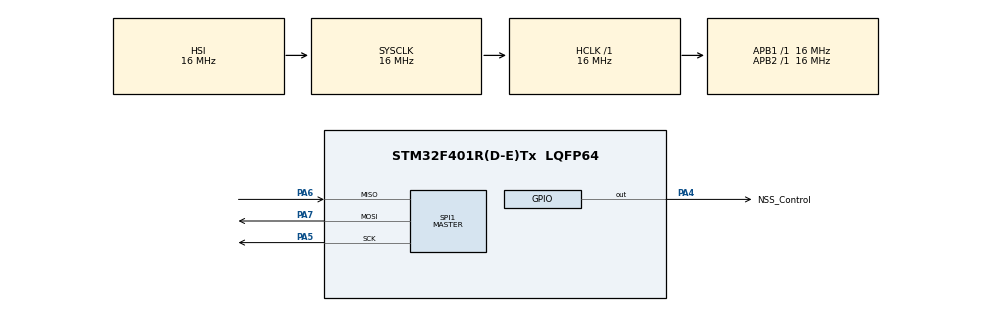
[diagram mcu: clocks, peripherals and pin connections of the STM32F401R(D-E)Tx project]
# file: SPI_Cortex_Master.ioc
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Dma.Request0=SPI1_RX
Dma.Request1=SPI1_TX
Dma.SPI1_RX.0.Direction=DMA_PERIPH_TO_MEMORY
Dma.SPI1_RX.0.FIFOMode=DMA_FIFOMODE_DISABLE
Dma.SPI1_RX.0.Instance=DMA2_Stream0
Dma.SPI1_RX.0.MemDataAlignment=DMA_MDATAALIGN_BYTE
Dma.SPI1_RX.0.MemInc=DMA_MINC_ENABLE
Dma.SPI1_RX.0.Mode=DMA_CIRCULAR
Dma.SPI1_RX.0.PeriphDataAlignment=DMA_PDATAALIGN_BYTE
Dma.SPI1_RX.0.PeriphInc=DMA_PINC_DISABLE
Dma.SPI1_RX.0.Priority=DMA_PRIORITY_LOW
Dma.SPI1_TX.1.Direction=DMA_MEMORY_TO_PERIPH
Dma.SPI1_TX.1.FIFOMode=DMA_FIFOMODE_DISABLE
Dma.SPI1_TX.1.Instance=DMA2_Stream3
Dma.SPI1_TX.1.MemDataAlignment=DMA_MDATAALIGN_BYTE
Dma.SPI1_TX.1.MemInc=DMA_MINC_ENABLE
Dma.SPI1_TX.1.Mode=DMA_CIRCULAR
Dma.SPI1_TX.1.PeriphDataAlignment=DMA_PDATAALIGN_BYTE
Dma.SPI1_TX.1.PeriphInc=DMA_PINC_DISABLE
Dma.SPI1_TX.1.Priority=DMA_PRIORITY_LOW
Mcu.Family=STM32F4
Mcu.Name=STM32F401R(D-E)Tx
Mcu.Package=LQFP64
NVIC.DMA2_Stream0_IRQn=true\:0\:0\:false\:false\:true\:false
NVIC.DMA2_Stream3_IRQn=true\:0\:0\:false\:false\:true\:false
NVIC.PriorityGroup=NVIC_PRIORITYGROUP_4
NVIC.SPI1_IRQn=true\:0\:0\:false\:false\:true\:true
PA4.GPIO_Label=NSS_Control
PA4.GPIO_Speed=GPIO_SPEED_FREQ_HIGH
PA4.Signal=GPIO_Output
PA5.Mode=Full_Duplex_Master
PA5.Signal=SPI1_SCK
PA6.Mode=Full_Duplex_Master
PA6.Signal=SPI1_MISO
PA7.Mode=Full_Duplex_Master
PA7.Signal=SPI1_MOSI
ProjectManager.HeapSize=0x200
ProjectManager.StackSize=0x400
ProjectManager.TargetToolchain=EWARM
RCC.AHBFreq_Value=16000000
RCC.APB1Freq_Value=16000000
RCC.APB2Freq_Value=16000000
RCC.CortexFreq_Value=16000000
RCC.HSE_VALUE=25000000
RCC.HSI_VALUE=16000000
RCC.LSE_VALUE=32768
RCC.SYSCLKFreq_VALUE=16000000
RCC.VCOOutputFreq_Value=192000000
SPI1.BaudRatePrescaler=SPI_BAUDRATEPRESCALER_8
SPI1.Direction=SPI_DIRECTION_2LINES
SPI1.Mode=SPI_MODE_MASTER
SPI1.VirtualType=VM_MASTER
board=SPI_Cortex_Master

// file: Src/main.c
/**
  ******************************************************************************
  * @file           : main.c
  * @brief          : Main program body
  ******************************************************************************
  ** This notice applies to any and all portions of this file
  * that are not between comment pairs USER CODE BEGIN and
  * USER CODE END. Other portions of this file, whether
  * inserted by the user or by software development tools
  * are owned by their respective copyright owners.
  *
  * COPYRIGHT(c) 2020 STMicroelectronics
  *
  * Redistribution and use in source and binary forms, with or without modification,
  * are permitted provided that the following conditions are met:
  *   1. Redistributions of source code must retain the above copyright notice,
  *      this list of conditions and the following disclaimer.
  *   2. Redistributions in binary form must reproduce the above copyright notice,
  *      this list of conditions and the following disclaimer in the documentation
  *      and/or other materials provided with the distribution.
  *   3. Neither the name of STMicroelectronics nor the names of its contributors
  *      may be used to endorse or promote products derived from this software
  *      without specific prior written permission.
  *
  * THIS SOFTWARE IS PROVIDED BY THE COPYRIGHT HOLDERS AND CONTRIBUTORS "AS IS"
  * AND ANY EXPRESS OR IMPLIED WARRANTIES, INCLUDING, BUT NOT LIMITED TO, THE
  * IMPLIED WARRANTIES OF MERCHANTABILITY AND FITNESS FOR A PARTICULAR PURPOSE ARE
  * DISCLAIMED. IN NO EVENT SHALL THE COPYRIGHT HOLDER OR CONTRIBUTORS BE LIABLE
  * FOR ANY DIRECT, INDIRECT, INCIDENTAL, SPECIAL, EXEMPLARY, OR CONSEQUENTIAL
  * DAMAGES (INCLUDING, BUT NOT LIMITED TO, PROCUREMENT OF SUBSTITUTE GOODS OR
  * SERVICES; LOSS OF USE, DATA, OR PROFITS; OR BUSINESS INTERRUPTION) HOWEVER
  * CAUSED AND ON ANY THEORY OF LIABILITY, WHETHER IN CONTRACT, STRICT LIABILITY,
  * OR TORT (INCLUDING NEGLIGENCE OR OTHERWISE) ARISING IN ANY WAY OUT OF THE USE
  * OF THIS SOFTWARE, EVEN IF ADVISED OF THE POSSIBILITY OF SUCH DAMAGE.
  *
  ******************************************************************************
  */
#include "main.h"
#include "stm32f4xx_hal.h"

SPI_HandleTypeDef hspi1;
DMA_HandleTypeDef hdma_spi1_rx;
DMA_HandleTypeDef hdma_spi1_tx;

/* USER CODE BEGIN PV */
/* Private variables ---------------------------------------------------------*/

/* USER CODE END PV */

void SystemClock_Config(void);
static void MX_GPIO_Init(void);
static void MX_DMA_Init(void);
static void MX_SPI1_Init(void);

/* USER CODE BEGIN PFP */
/* Private function prototypes -----------------------------------------------*/

/* USER CODE END PFP */

/* USER CODE BEGIN 0 */
uint8_t dataTx[6] = {9,7,0,7,2,2};
uint8_t dataRx[6];

#define SPI_En          HAL_GPIO_WritePin(GPIOA,GPIO_PIN_4,GPIO_PIN_RESET);
#define SPI_Dis         HAL_GPIO_WritePin(GPIOA,GPIO_PIN_4,GPIO_PIN_SET);
/* USER CODE END 0 */

int main(void)
{

  /* MCU Configuration----------------------------------------------------------*/

  /* Reset of all peripherals, Initializes the Flash interface and the Systick. */
  HAL_Init();

  /* Configure the system clock */
  SystemClock_Config();

  /* Initialize all configured peripherals */
  MX_GPIO_Init();
  MX_DMA_Init();
  MX_SPI1_Init();
  /* USER CODE BEGIN 2 */
  //HAL_SPI_TransmitReceive_IT(&hspi1, dataTx, dataRx, 6);
  //HAL_SPI_TransmitReceive_DMA(&hspi1, dataTx, dataRx, 6);
  /* USER CODE END 2 */

  /* Infinite loop */
  while (1)
  {
    HAL_SPI_Transmit(&hspi1,dataTx, 6,100);
    HAL_Delay(500);
  }

}

void SystemClock_Config(void)
{

  RCC_OscInitTypeDef RCC_OscInitStruct;
  RCC_ClkInitTypeDef RCC_ClkInitStruct;

    /**Configure the main internal regulator output voltage
    */
  __HAL_RCC_PWR_CLK_ENABLE();

  __HAL_PWR_VOLTAGESCALING_CONFIG(PWR_REGULATOR_VOLTAGE_SCALE2);

    /**Initializes the CPU, AHB and APB busses clocks
    */
  RCC_OscInitStruct.OscillatorType = RCC_OSCILLATORTYPE_HSI;
  RCC_OscInitStruct.HSIState = RCC_HSI_ON;
  RCC_OscInitStruct.HSICalibrationValue = 16;
  RCC_OscInitStruct.PLL.PLLState = RCC_PLL_NONE;
  if (HAL_RCC_OscConfig(&RCC_OscInitStruct) != HAL_OK)
  {
    _Error_Handler(__FILE__, __LINE__);
  }

    /**Initializes the CPU, AHB and APB busses clocks
    */
  RCC_ClkInitStruct.ClockType = RCC_CLOCKTYPE_HCLK|RCC_CLOCKTYPE_SYSCLK
                              |RCC_CLOCKTYPE_PCLK1|RCC_CLOCKTYPE_PCLK2;
  RCC_ClkInitStruct.SYSCLKSource = RCC_SYSCLKSOURCE_HSI;
  RCC_ClkInitStruct.AHBCLKDivider = RCC_SYSCLK_DIV1;
  RCC_ClkInitStruct.APB1CLKDivider = RCC_HCLK_DIV1;
  RCC_ClkInitStruct.APB2CLKDivider = RCC_HCLK_DIV1;

  if (HAL_RCC_ClockConfig(&RCC_ClkInitStruct, FLASH_LATENCY_0) != HAL_OK)
  {
    _Error_Handler(__FILE__, __LINE__);
  }

    /**Configure the Systick interrupt time
    */
  HAL_SYSTICK_Config(HAL_RCC_GetHCLKFreq()/1000);

    /**Configure the Systick
    */
  HAL_SYSTICK_CLKSourceConfig(SYSTICK_CLKSOURCE_HCLK);

  /* SysTick_IRQn interrupt configuration */
  HAL_NVIC_SetPriority(SysTick_IRQn, 0, 0);
}

/* SPI1 init function */
static void MX_SPI1_Init(void)
{

  /* SPI1 parameter configuration*/
  hspi1.Instance = SPI1;
  hspi1.Init.Mode = SPI_MODE_MASTER;
  hspi1.Init.Direction = SPI_DIRECTION_2LINES;
  hspi1.Init.DataSize = SPI_DATASIZE_8BIT;
  hspi1.Init.CLKPolarity = SPI_POLARITY_LOW;
  hspi1.Init.CLKPhase = SPI_PHASE_1EDGE;
  hspi1.Init.NSS = SPI_NSS_SOFT;
  hspi1.Init.BaudRatePrescaler = SPI_BAUDRATEPRESCALER_8;
  hspi1.Init.FirstBit = SPI_FIRSTBIT_MSB;
  hspi1.Init.TIMode = SPI_TIMODE_DISABLE;
  hspi1.Init.CRCCalculation = SPI_CRCCALCULATION_DISABLE;
  hspi1.Init.CRCPolynomial = 10;
  if (HAL_SPI_Init(&hspi1) != HAL_OK)
  {
    _Error_Handler(__FILE__, __LINE__);
  }

}

static void MX_DMA_Init(void)
{
  /* DMA controller clock enable */
  __HAL_RCC_DMA2_CLK_ENABLE();

  /* DMA interrupt init */
  /* DMA2_Stream0_IRQn interrupt configuration */
  HAL_NVIC_SetPriority(DMA2_Stream0_IRQn, 0, 0);
  HAL_NVIC_EnableIRQ(DMA2_Stream0_IRQn);
  /* DMA2_Stream3_IRQn interrupt configuration */
  HAL_NVIC_SetPriority(DMA2_Stream3_IRQn, 0, 0);
  HAL_NVIC_EnableIRQ(DMA2_Stream3_IRQn);

}

/** Configure pins as
        * Analog
        * Input
        * Output
        * EVENT_OUT
        * EXTI
*/
static void MX_GPIO_Init(void)
{

  GPIO_InitTypeDef GPIO_InitStruct;

  /* GPIO Ports Clock Enable */
  __HAL_RCC_GPIOA_CLK_ENABLE();

  /*Configure GPIO pin Output Level */
  HAL_GPIO_WritePin(NSS_Control_GPIO_Port, NSS_Control_Pin, GPIO_PIN_RESET);

  /*Configure GPIO pin : NSS_Control_Pin */
  GPIO_InitStruct.Pin = NSS_Control_Pin;
  GPIO_InitStruct.Mode = GPIO_MODE_OUTPUT_PP;
  GPIO_InitStruct.Pull = GPIO_NOPULL;
  GPIO_InitStruct.Speed = GPIO_SPEED_FREQ_HIGH;
  HAL_GPIO_Init(NSS_Control_GPIO_Port, &GPIO_InitStruct);

}

void _Error_Handler(char *file, int line)
{
  while(1)
  {
  }
}

/************************ (C) COPYRIGHT STMicroelectronics *****END OF FILE****/
